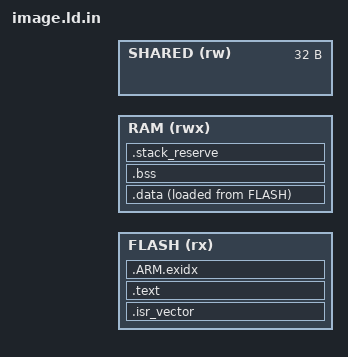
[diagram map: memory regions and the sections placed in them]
/* Generated by CMake for @LD_IMAGE_NAME@. Do not edit.
 *
 * The bootloader and every application slot use this one script with a
 * different FLASH origin. The last 32 bytes of RAM are excluded from both so
 * the bootloader can hand information to the application across the jump
 * and the application can leave a request for the bootloader across a reset. */

MEMORY
{
    FLASH  (rx)  : ORIGIN = @LD_FLASH_ORIGIN@, LENGTH = @LD_FLASH_LENGTH@
    RAM    (rwx) : ORIGIN = @SOTA_RAM_BASE@, LENGTH = @LD_RAM_LENGTH@
    SHARED (rw)  : ORIGIN = @LD_SHARED_ORIGIN@, LENGTH = 32
}

ENTRY(Reset_Handler)

_estack = ORIGIN(RAM) + LENGTH(RAM);
_sota_handoff = ORIGIN(SHARED);
_min_stack_size = 0x2000;

SECTIONS
{
    .isr_vector :
    {
        KEEP(*(.isr_vector))
    } > FLASH

    .text :
    {
        *(.text*)
        *(.rodata*)
        . = ALIGN(4);
    } > FLASH

    .ARM.exidx :
    {
        *(.ARM.exidx*)
    } > FLASH

    _sidata = LOADADDR(.data);

    .data :
    {
        . = ALIGN(4);
        _sdata = .;
        *(.data*)
        . = ALIGN(8);
        _edata = .;
    } > RAM AT > FLASH

    .bss (NOLOAD) :
    {
        . = ALIGN(4);
        _sbss = .;
        *(.bss*)
        *(COMMON)
        . = ALIGN(4);
        _ebss = .;
        end = .;
    } > RAM

    /* Fails the link if static data leaves less than _min_stack_size. */
    .stack_reserve (NOLOAD) :
    {
        . = ALIGN(8);
        . = . + _min_stack_size;
    } > RAM
}
